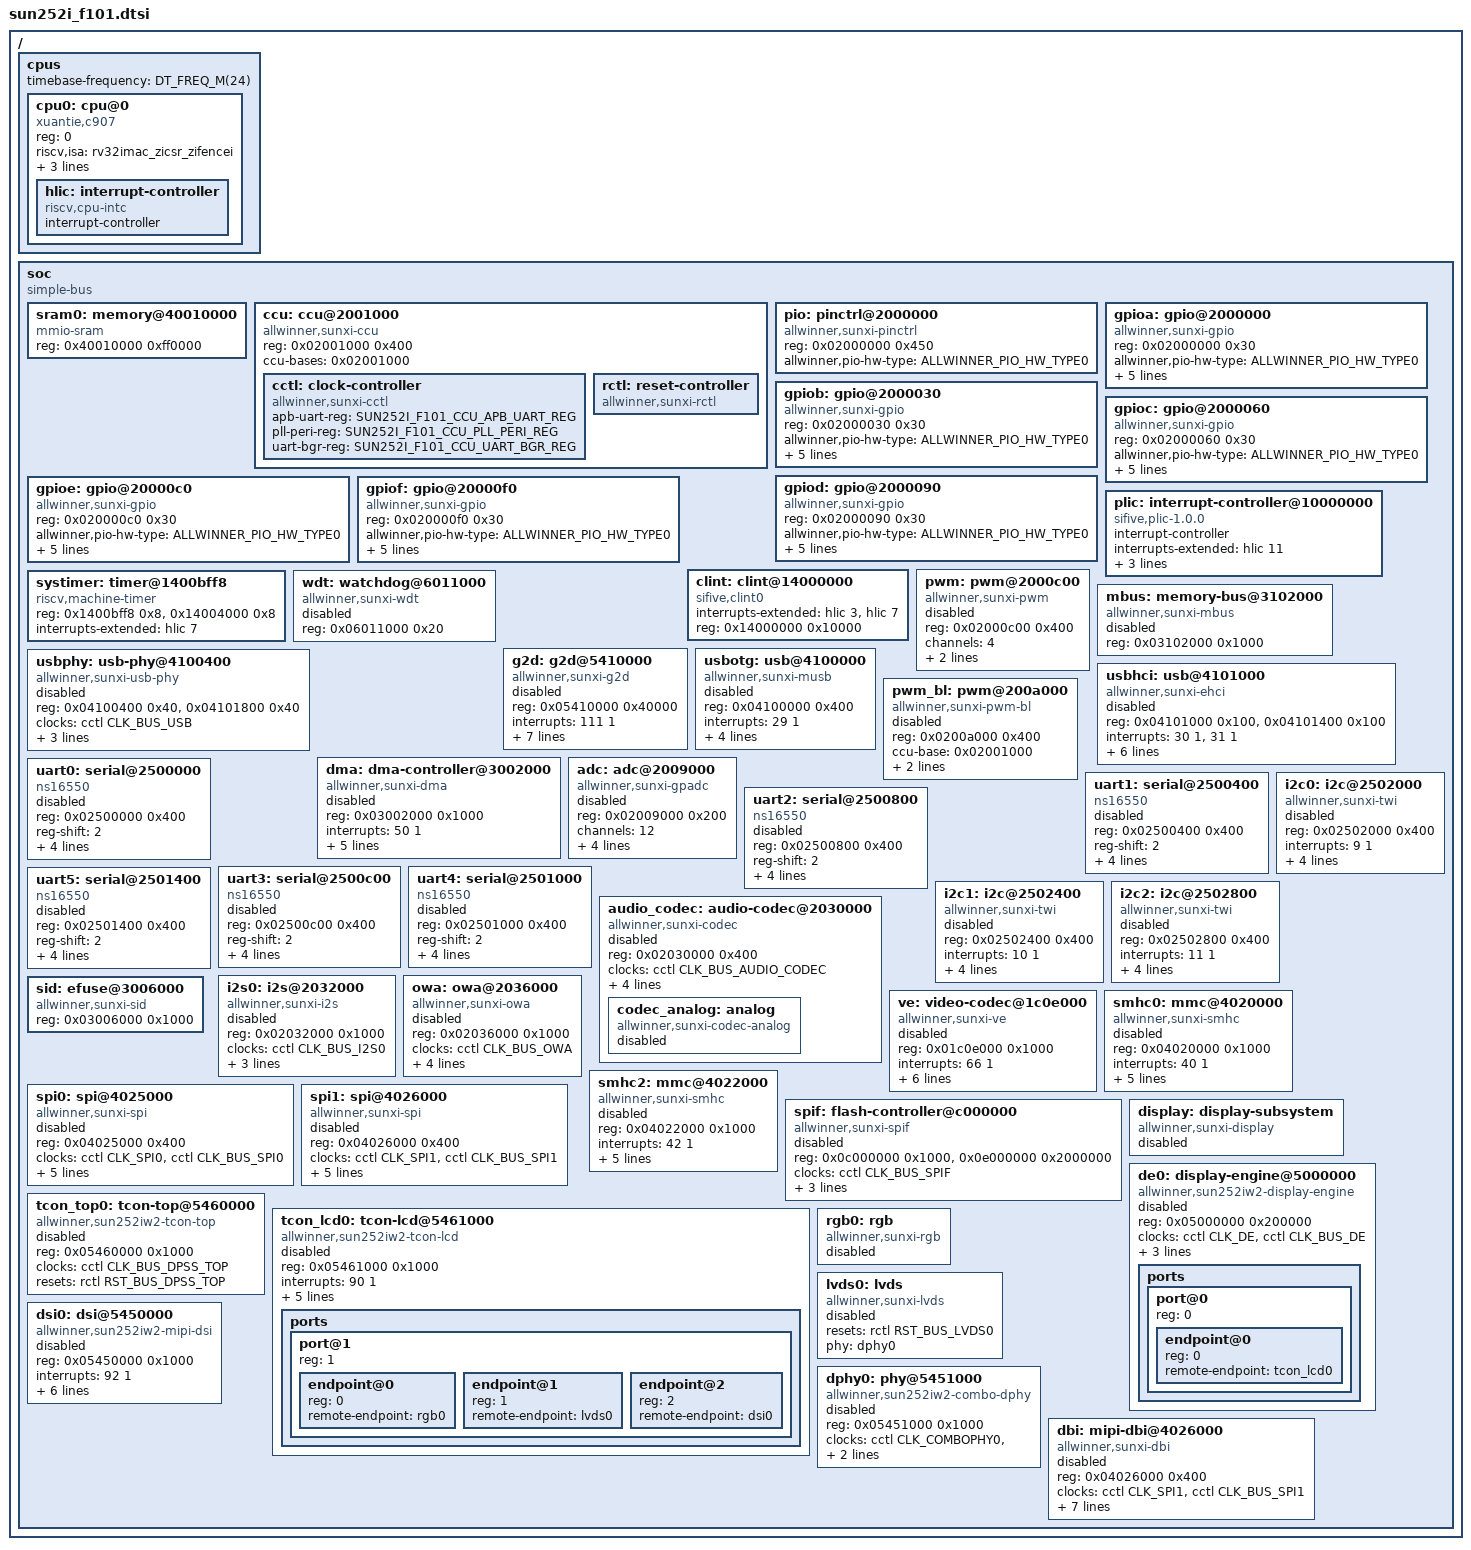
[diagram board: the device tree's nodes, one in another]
/*
 * Copyright (c) 2026 Yuzuki Tsuru
 *
 * SPDX-License-Identifier: Apache-2.0
 */

/dts-v1/;

#include <freq.h>
#include <zephyr/dt-bindings/clock/sun252i-f101-ccu.h>
#include <zephyr/dt-bindings/pinctrl/allwinner-pinctrl.h>
#include <zephyr/dt-bindings/gpio/gpio.h>

/ {
	#address-cells = <1>;
	#size-cells = <1>;

	cpus {
		#address-cells = <1>;
		#size-cells = <0>;
		timebase-frequency = <DT_FREQ_M(24)>;

		cpu0: cpu@0 {
			compatible = "xuantie,c907", "riscv";
			device_type = "cpu";
			reg = <0>;
			riscv,isa = "rv32imac_zicsr_zifencei";
			clock-frequency = <DT_FREQ_M(24)>;
			d-cache-line-size = <64>;
			i-cache-line-size = <64>;

			hlic: interrupt-controller {
				compatible = "riscv,cpu-intc";
				#address-cells = <0>;
				#interrupt-cells = <1>;
				interrupt-controller;
			};
		};
	};

	soc {
		#address-cells = <1>;
		#size-cells = <1>;
		compatible = "simple-bus";
		ranges;

		/* Internal SRAM/PSRAM, code loaded here by the bootloader */
		sram0: memory@40010000 {
			compatible = "mmio-sram";
			reg = <0x40010000 0xff0000>;
		};

		ccu: ccu@2001000 {
			compatible = "allwinner,sunxi-ccu";
			reg = <0x02001000 0x400>;
			ccu-bases = <0x02001000>;
			#address-cells = <1>;
			#size-cells = <0>;

			cctl: clock-controller {
				compatible = "allwinner,sunxi-cctl";
				apb-uart-reg = <SUN252I_F101_CCU_APB_UART_REG>;
				pll-peri-reg = <SUN252I_F101_CCU_PLL_PERI_REG>;
				uart-bgr-reg = <SUN252I_F101_CCU_UART_BGR_REG>;
				#clock-cells = <1>;
				status = "okay";
			};

			rctl: reset-controller {
				compatible = "allwinner,sunxi-rctl";
				#reset-cells = <1>;
				status = "okay";
			};
		};

		pio: pinctrl@2000000 {
			compatible = "allwinner,sunxi-pinctrl";
			reg = <0x02000000 0x450>;
			allwinner,pio-hw-type = <ALLWINNER_PIO_HW_TYPE0>;
			status = "okay";
		};

		gpioa: gpio@2000000 {
			compatible = "allwinner,sunxi-gpio";
			reg = <0x02000000 0x30>;
			allwinner,pio-hw-type = <ALLWINNER_PIO_HW_TYPE0>;
			allwinner,bank = <0>;
			gpio-controller;
			#gpio-cells = <2>;
			ngpios = <32>;
			interrupts = <67 1>;
			interrupt-parent = <&plic>;
			status = "okay";
		};

		gpiob: gpio@2000030 {
			compatible = "allwinner,sunxi-gpio";
			reg = <0x02000030 0x30>;
			allwinner,pio-hw-type = <ALLWINNER_PIO_HW_TYPE0>;
			allwinner,bank = <1>;
			gpio-controller;
			#gpio-cells = <2>;
			ngpios = <32>;
			interrupts = <69 1>;
			interrupt-parent = <&plic>;
			status = "okay";
		};

		gpioc: gpio@2000060 {
			compatible = "allwinner,sunxi-gpio";
			reg = <0x02000060 0x30>;
			allwinner,pio-hw-type = <ALLWINNER_PIO_HW_TYPE0>;
			allwinner,bank = <2>;
			gpio-controller;
			#gpio-cells = <2>;
			ngpios = <32>;
			interrupts = <71 1>;
			interrupt-parent = <&plic>;
			status = "okay";
		};

		gpiod: gpio@2000090 {
			compatible = "allwinner,sunxi-gpio";
			reg = <0x02000090 0x30>;
			allwinner,pio-hw-type = <ALLWINNER_PIO_HW_TYPE0>;
			allwinner,bank = <3>;
			gpio-controller;
			#gpio-cells = <2>;
			ngpios = <32>;
			interrupts = <73 1>;
			interrupt-parent = <&plic>;
			status = "okay";
		};

		gpioe: gpio@20000c0 {
			compatible = "allwinner,sunxi-gpio";
			reg = <0x020000c0 0x30>;
			allwinner,pio-hw-type = <ALLWINNER_PIO_HW_TYPE0>;
			allwinner,bank = <4>;
			gpio-controller;
			#gpio-cells = <2>;
			ngpios = <32>;
			interrupts = <75 1>;
			interrupt-parent = <&plic>;
			status = "okay";
		};

		gpiof: gpio@20000f0 {
			compatible = "allwinner,sunxi-gpio";
			reg = <0x020000f0 0x30>;
			allwinner,pio-hw-type = <ALLWINNER_PIO_HW_TYPE0>;
			allwinner,bank = <5>;
			gpio-controller;
			#gpio-cells = <2>;
			ngpios = <32>;
			interrupts = <77 1>;
			interrupt-parent = <&plic>;
			status = "okay";
		};

		plic: interrupt-controller@10000000 {
			compatible = "sifive,plic-1.0.0";
			#address-cells = <0>;
			#interrupt-cells = <2>;
			interrupt-controller;
			interrupts-extended = <&hlic 11>;
			reg = <0x10000000 0x210000>;
			riscv,max-priority = <7>;
			riscv,ndev = <192>;
		};

		/* C907 CLINT: MSIP at 0x14000000, mtimecmp at 0x14004000 and
		 * mtime at 0x1400bff8. The node provides the machine-interrupt
		 * wiring for the SMP IPIs.
		 */
		clint: clint@14000000 {
			compatible = "sifive,clint0";
			interrupts-extended = <&hlic 3 &hlic 7>;
			reg = <0x14000000 0x10000>;
		};

		/* Standard RISC-V machine timer. The C907 exposes the mtime
		 * counter at CLINT + 0xbff8 and mtimecmp at CLINT + 0x4000.
		 */
		systimer: timer@1400bff8 {
			compatible = "riscv,machine-timer";
			reg = <0x1400bff8 0x8>, <0x14004000 0x8>;
			reg-names = "mtime", "mtimecmp";
			interrupts-extended = <&hlic 7>;
		};

		wdt: watchdog@6011000 {
			compatible = "allwinner,sunxi-wdt";
			reg = <0x06011000 0x20>;
			status = "disabled";
		};

		pwm: pwm@2000c00 {
			compatible = "allwinner,sunxi-pwm";
			#pwm-cells = <3>;
			reg = <0x02000c00 0x400>;
			channels = <4>;
			clocks = <&cctl CLK_BUS_PWM>;
			resets = <&rctl RST_BUS_PWM>;
			status = "disabled";
		};

		mbus: memory-bus@3102000 {
			compatible = "allwinner,sunxi-mbus";
			#address-cells = <1>;
			#size-cells = <0>;
			reg = <0x03102000 0x1000>;
			status = "disabled";
		};

		g2d: g2d@5410000 {
			compatible = "allwinner,sunxi-g2d";
			reg = <0x05410000 0x40000>;
			interrupts = <111 1>;
			interrupt-parent = <&plic>;
			clocks = <&cctl CLK_G2D>, <&cctl CLK_BUS_G2D>, <&cctl CLK_BUS_G2D_M>;
			clock-names = "mod", "bus", "mbus";
			resets = <&rctl RST_BUS_G2D>;
			ccu-base = <0x02001000>;
			mod-clk-reg = <0x630>;
			clock-frequency = <300000000>;
			status = "disabled";
		};

		usbphy: usb-phy@4100400 {
			compatible = "allwinner,sunxi-usb-phy";
			#phy-cells = <0>;
			/* OTG glue block, HCI PHY/SIE block */
			reg = <0x04100400 0x40>, <0x04101800 0x40>;
			reg-names = "otg", "hci";
			clocks = <&cctl CLK_BUS_USB>;
			resets = <&rctl RST_USB_PHY0>;
			sram-remap-reg = <0x03000004>;
			sram-remap-clear = <0x0a000000>;
			status = "disabled";
		};

		usbotg: usb@4100000 {
			compatible = "allwinner,sunxi-musb";
			reg = <0x04100000 0x400>;
			interrupts = <29 1>;
			interrupt-parent = <&plic>;
			clocks = <&cctl CLK_BUS_USB_OTG>;
			resets = <&rctl RST_BUS_USB_OTG>;
			phys = <&usbphy>;
			status = "disabled";
		};

		usbhci: usb@4101000 {
			compatible = "allwinner,sunxi-ehci";
			/* EHCI and OHCI register windows */
			reg = <0x04101000 0x100>, <0x04101400 0x100>;
			reg-names = "ehci", "ohci";
			interrupts = <30 1>, <31 1>;
			interrupt-names = "ehci", "ohci";
			interrupt-parent = <&plic>;
			clocks = <&cctl CLK_BUS_USB_EHCI>, <&cctl CLK_BUS_USB_OHCI>;
			clock-names = "ehci", "ohci";
			resets = <&rctl RST_BUS_USB_EHCI>, <&rctl RST_BUS_USB_OHCI>;
			phys = <&usbphy>;
			status = "disabled";
		};

		pwm_bl: pwm@200a000 {
			compatible = "allwinner,sunxi-pwm-bl";
			#pwm-cells = <3>;
			reg = <0x0200a000 0x400>;
			ccu-base = <0x02001000>;
			mod-clk-reg = <0x790>;
			bus-clk-reg = <0x794>;
			status = "disabled";
		};

		dma: dma-controller@3002000 {
			compatible = "allwinner,sunxi-dma";
			reg = <0x03002000 0x1000>;
			interrupts = <50 1>;
			interrupt-parent = <&plic>;
			clocks = <&cctl CLK_BUS_DMA>, <&cctl CLK_BUS_DMA_M>;
			clock-names = "bus", "mbus";
			resets = <&rctl RST_BUS_DMA>;
			#dma-cells = <1>;
			dma-channels = <12>;
			dma-requests = <64>;
			status = "disabled";
		};

		adc: adc@2009000 {
			compatible = "allwinner,sunxi-gpadc";
			#io-channel-cells = <1>;
			reg = <0x02009000 0x200>;
			channels = <12>;
			vref-mv = <1800>;
			sample-rate = <1000>;
			clocks = <&cctl CLK_BUS_GPADC>;
			resets = <&rctl RST_BUS_GPADC>;
			status = "disabled";
		};

		uart0: serial@2500000 {
			compatible = "ns16550", "snps,dw-apb-uart";
			reg = <0x02500000 0x400>;
			reg-shift = <2>;
			interrupts = <2 1>;
			interrupt-parent = <&plic>;
			clocks = <&cctl CLK_BUS_UART0>;
			resets = <&rctl RST_BUS_UART0>;
			status = "disabled";
		};

		uart1: serial@2500400 {
			compatible = "ns16550", "snps,dw-apb-uart";
			reg = <0x02500400 0x400>;
			reg-shift = <2>;
			interrupts = <3 1>;
			interrupt-parent = <&plic>;
			clocks = <&cctl CLK_BUS_UART1>;
			resets = <&rctl RST_BUS_UART1>;
			status = "disabled";
		};

		uart2: serial@2500800 {
			compatible = "ns16550", "snps,dw-apb-uart";
			reg = <0x02500800 0x400>;
			reg-shift = <2>;
			interrupts = <4 1>;
			interrupt-parent = <&plic>;
			clocks = <&cctl CLK_BUS_UART2>;
			resets = <&rctl RST_BUS_UART2>;
			status = "disabled";
		};

		uart3: serial@2500c00 {
			compatible = "ns16550", "snps,dw-apb-uart";
			reg = <0x02500c00 0x400>;
			reg-shift = <2>;
			interrupts = <5 1>;
			interrupt-parent = <&plic>;
			clocks = <&cctl CLK_BUS_UART3>;
			resets = <&rctl RST_BUS_UART3>;
			status = "disabled";
		};

		uart4: serial@2501000 {
			compatible = "ns16550", "snps,dw-apb-uart";
			reg = <0x02501000 0x400>;
			reg-shift = <2>;
			interrupts = <6 1>;
			interrupt-parent = <&plic>;
			clocks = <&cctl CLK_BUS_UART4>;
			resets = <&rctl RST_BUS_UART4>;
			status = "disabled";
		};

		uart5: serial@2501400 {
			compatible = "ns16550", "snps,dw-apb-uart";
			reg = <0x02501400 0x400>;
			reg-shift = <2>;
			interrupts = <7 1>;
			interrupt-parent = <&plic>;
			clocks = <&cctl CLK_BUS_UART5>;
			resets = <&rctl RST_BUS_UART5>;
			status = "disabled";
		};

		i2c0: i2c@2502000 {
			compatible = "allwinner,sunxi-twi";
			#address-cells = <1>;
			#size-cells = <0>;
			reg = <0x02502000 0x400>;
			interrupts = <9 1>;
			interrupt-parent = <&plic>;
			clocks = <&cctl CLK_BUS_TWI0>;
			resets = <&rctl RST_BUS_TWI0>;
			clock-frequency = <100000>;
			status = "disabled";
		};

		i2c1: i2c@2502400 {
			compatible = "allwinner,sunxi-twi";
			#address-cells = <1>;
			#size-cells = <0>;
			reg = <0x02502400 0x400>;
			interrupts = <10 1>;
			interrupt-parent = <&plic>;
			clocks = <&cctl CLK_BUS_TWI1>;
			resets = <&rctl RST_BUS_TWI1>;
			clock-frequency = <100000>;
			status = "disabled";
		};

		i2c2: i2c@2502800 {
			compatible = "allwinner,sunxi-twi";
			#address-cells = <1>;
			#size-cells = <0>;
			reg = <0x02502800 0x400>;
			interrupts = <11 1>;
			interrupt-parent = <&plic>;
			clocks = <&cctl CLK_BUS_TWI2>;
			resets = <&rctl RST_BUS_TWI2>;
			clock-frequency = <100000>;
			status = "disabled";
		};

		/* Audio: PLL_AUDIO1 and the module clocks are programmed by the drivers */
		audio_codec: audio-codec@2030000 {
			compatible = "allwinner,sunxi-codec";
			reg = <0x02030000 0x400>;
			clocks = <&cctl CLK_BUS_AUDIO_CODEC>;
			clock-names = "bus";
			resets = <&rctl RST_BUS_AUDIO_CODEC>;
			dac-clock-reg = <0xa50>;
			adc-clock-reg = <0xa54>;
			dmas = <&dma 1>, <&dma 2>;
			dma-names = "tx", "rx";
			status = "disabled";

			codec_analog: analog {
				compatible = "allwinner,sunxi-codec-analog";
				status = "disabled";
			};
		};

		i2s0: i2s@2032000 {
			#address-cells = <1>;
			#size-cells = <0>;
			compatible = "allwinner,sunxi-i2s";
			reg = <0x02032000 0x1000>;
			clocks = <&cctl CLK_BUS_I2S0>;
			clock-names = "bus";
			resets = <&rctl RST_BUS_I2S0>;
			clock-reg = <0xa10>;
			dmas = <&dma 3>, <&dma 4>;
			dma-names = "tx", "rx";
			status = "disabled";
		};

		owa: owa@2036000 {
			#address-cells = <1>;
			#size-cells = <0>;
			compatible = "allwinner,sunxi-owa";
			reg = <0x02036000 0x1000>;
			clocks = <&cctl CLK_BUS_OWA>;
			clock-names = "bus";
			resets = <&rctl RST_BUS_OWA>;
			tx-clock-reg = <0xa24>;
			rx-clock-reg = <0xa28>;
			dmas = <&dma 5>, <&dma 6>;
			dma-names = "tx", "rx";
			status = "disabled";
		};

		/* fuses: the 128 bit chip identifier is the first four words */
		sid: efuse@3006000 {
			compatible = "allwinner,sunxi-sid";
			reg = <0x03006000 0x1000>;
		};

		ve: video-codec@1c0e000 {
			compatible = "allwinner,sunxi-ve";
			reg = <0x01c0e000 0x1000>;
			interrupts = <66 1>;
			interrupt-parent = <&plic>;
			clocks = <&cctl CLK_VE>, <&cctl CLK_BUS_VE>, <&cctl CLK_BUS_VE_M>;
			clock-names = "mod", "bus", "mbus";
			resets = <&rctl RST_BUS_VE>;
			clock-reg = <0x690>;
			sram-ctrl-reg = <0x03000000>;
			status = "disabled";
		};

		smhc0: mmc@4020000 {
			compatible = "allwinner,sunxi-smhc";
			reg = <0x04020000 0x1000>;
			interrupts = <40 1>;
			interrupt-parent = <&plic>;
			clocks = <&cctl CLK_SMHC0>, <&cctl CLK_BUS_SMHC0>;
			clock-names = "mod", "bus";
			resets = <&rctl RST_BUS_SMHC0>;
			clock-reg = <0x830>;
			max-bus-freq = <50000000>;
			status = "disabled";
		};

		smhc2: mmc@4022000 {
			compatible = "allwinner,sunxi-smhc";
			reg = <0x04022000 0x1000>;
			interrupts = <42 1>;
			interrupt-parent = <&plic>;
			clocks = <&cctl CLK_SMHC2>, <&cctl CLK_BUS_SMHC2>;
			clock-names = "mod", "bus";
			resets = <&rctl RST_BUS_SMHC2>;
			clock-reg = <0x838>;
			max-bus-freq = <50000000>;
			status = "disabled";
		};

		spi0: spi@4025000 {
			compatible = "allwinner,sunxi-spi";
			#address-cells = <1>;
			#size-cells = <0>;
			reg = <0x04025000 0x400>;
			clocks = <&cctl CLK_SPI0>, <&cctl CLK_BUS_SPI0>;
			clock-names = "mod", "bus";
			resets = <&rctl RST_BUS_SPI0>;
			clock-frequency = <10000000>;
			clock-reg = <0x940>;
			dmas = <&dma 7>;
			dma-names = "rx";
			dma-slot = <22>;
			status = "disabled";
		};

		/*
		 * SPI NOR flash controller: command/descriptor DMA registers and
		 * the window through which the flash can be read and executed
		 * in place.
		 */
		spif: flash-controller@c000000 {
			compatible = "allwinner,sunxi-spif";
			reg = <0x0c000000 0x1000>, <0x0e000000 0x2000000>;
			reg-names = "ctrl", "xip";
			clocks = <&cctl CLK_BUS_SPIF>;
			clock-names = "bus";
			resets = <&rctl RST_BUS_SPIF>;
			clock-reg = <0x980>;
			clock-frequency = <100000000>;
			status = "disabled";
		};

		spi1: spi@4026000 {
			compatible = "allwinner,sunxi-spi";
			#address-cells = <1>;
			#size-cells = <0>;
			reg = <0x04026000 0x400>;
			clocks = <&cctl CLK_SPI1>, <&cctl CLK_BUS_SPI1>;
			clock-names = "mod", "bus";
			resets = <&rctl RST_BUS_SPI1>;
			clock-frequency = <10000000>;
			clock-reg = <0x944>;
			dmas = <&dma 8>;
			dma-names = "rx";
			dma-slot = <23>;
			status = "disabled";
		};

		/*
		 * Display pipeline (see dts/bindings/display/sunxi):
		 *
		 *   de0 -> tcon_lcd0 -+-> rgb0  -> panel
		 *                     +-> lvds0 -> panel  (via dphy0)
		 *                     +-> dsi0  -> panel  (via dphy0)
		 *
		 * The boards enable the blocks they wire and add the panel and
		 * backlight nodes; the links below only take effect when both
		 * ends are enabled.
		 */
		display: display-subsystem {
			compatible = "allwinner,sunxi-display";
			status = "disabled";
		};

		de0: display-engine@5000000 {
			compatible = "allwinner,sun252iw2-display-engine";
			reg = <0x05000000 0x200000>;
			clocks = <&cctl CLK_DE>, <&cctl CLK_BUS_DE>;
			clock-names = "mod", "bus";
			clock-parents = <CLK_PLL_PERI_2X 0>;
			clock-rates = <300000000 0>;
			resets = <&rctl RST_BUS_DE>;
			reset-names = "bus";
			status = "disabled";

			ports {
				#address-cells = <1>;
				#size-cells = <0>;

				port@0 {
					reg = <0>;
					#address-cells = <1>;
					#size-cells = <0>;

					endpoint@0 {
						reg = <0>;
						remote-endpoint = <&tcon_lcd0>;
					};
				};
			};
		};

		tcon_top0: tcon-top@5460000 {
			compatible = "allwinner,sun252iw2-tcon-top";
			reg = <0x05460000 0x1000>;
			clocks = <&cctl CLK_BUS_DPSS_TOP>;
			clock-names = "bus";
			resets = <&rctl RST_BUS_DPSS_TOP>;
			reset-names = "bus";
			status = "disabled";
		};

		tcon_lcd0: tcon-lcd@5461000 {
			compatible = "allwinner,sun252iw2-tcon-lcd";
			reg = <0x05461000 0x1000>;
			interrupts = <90 1>;
			interrupt-parent = <&plic>;
			clocks = <&cctl CLK_TCONLCD>, <&cctl CLK_BUS_TCONLCD>;
			clock-names = "mod", "bus";
			clock-parents = <CLK_PLL_VIDEO0_4X 0>;
			resets = <&rctl RST_BUS_TCONLCD>;
			reset-names = "bus";
			top = <&tcon_top0>;
			status = "disabled";

			ports {
				#address-cells = <1>;
				#size-cells = <0>;

				port@1 {
					reg = <1>;
					#address-cells = <1>;
					#size-cells = <0>;

					endpoint@0 {
						reg = <0>;
						remote-endpoint = <&rgb0>;
					};

					endpoint@1 {
						reg = <1>;
						remote-endpoint = <&lvds0>;
					};

					endpoint@2 {
						reg = <2>;
						remote-endpoint = <&dsi0>;
					};
				};
			};
		};

		rgb0: rgb {
			compatible = "allwinner,sunxi-rgb";
			status = "disabled";
		};

		lvds0: lvds {
			compatible = "allwinner,sunxi-lvds";
			resets = <&rctl RST_BUS_LVDS0>;
			reset-names = "bus";
			phy = <&dphy0>;
			status = "disabled";
		};

		dsi0: dsi@5450000 {
			compatible = "allwinner,sun252iw2-mipi-dsi";
			reg = <0x05450000 0x1000>;
			interrupts = <92 1>;
			interrupt-parent = <&plic>;
			clocks = <&cctl CLK_DSI>, <&cctl CLK_BUS_DSI>;
			clock-names = "mod", "bus";
			clock-parents = <CLK_PLL_PERI_1X 0>;
			clock-rates = <150000000 0>;
			resets = <&rctl RST_BUS_DSI>;
			reset-names = "bus";
			phy = <&dphy0>;
			status = "disabled";
		};

		dphy0: phy@5451000 {
			compatible = "allwinner,sun252iw2-combo-dphy";
			reg = <0x05451000 0x1000>;
			clocks = <&cctl CLK_COMBOPHY0>, <&cctl CLK_BUS_COMBOPHY0>;
			clock-names = "mod", "bus";
			clock-parents = <CLK_PLL_VIDEO0_4X 0>;
			status = "disabled";
		};

		dbi: mipi-dbi@4026000 {
			compatible = "allwinner,sunxi-dbi";
			#address-cells = <1>;
			#size-cells = <0>;
			reg = <0x04026000 0x400>;
			clocks = <&cctl CLK_SPI1>, <&cctl CLK_BUS_SPI1>;
			clock-names = "mod", "bus";
			resets = <&rctl RST_BUS_SPI1>;
			clock-reg = <0x944>;
			clock-frequency = <5000000>;
			spi-dev = <&spi1>;
			dmas = <&dma 0>;
			dma-names = "tx";
			cs-gpios = <&gpiod 0 GPIO_ACTIVE_LOW>;
			reset-gpios = <&gpiod 4 GPIO_ACTIVE_LOW>;
			status = "disabled";
		};
	};
};
